# STM32L4R5AGI6 register map
File version: 1.0
Registers are 32-bit, access not given, reset 0x0 unless marked. A register's access mark holds for its fields unless they carry their own. Offsets are from the block's base; [hi:lo] are bit positions; {n}, {i} and the like mark numbered series; 'fields as' and 'values as' point back to an identical list.

## TIM6
Base 0x40001000
Same registers: TIM7 0x40001400
0x00 CR1
  [11] UIFREMA, [7] ARPE, [31:4] s, [3] OPM, [2] URS, [1] UDIS, [0] CEN
0x04 CR2
  [6:4] MMS, [31:0] s
0x0C DIER
  [8] UDE, [31:1] s, [0] UIE
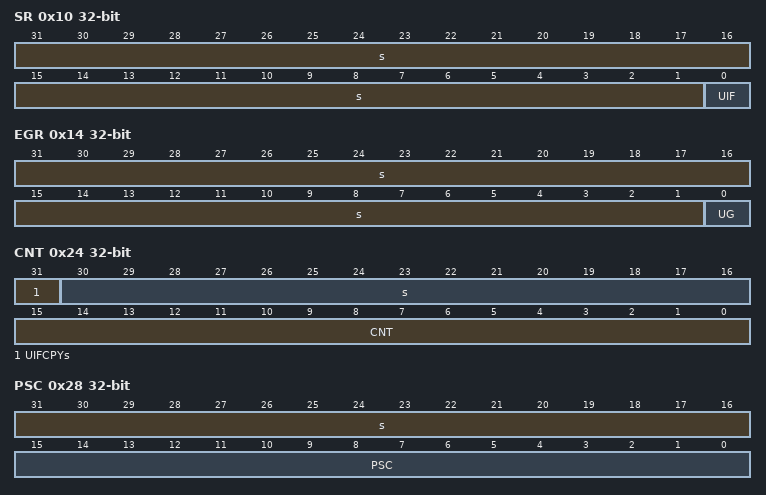
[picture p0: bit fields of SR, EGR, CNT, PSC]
0x10 SR
  [31:1] s, [0] UIF
0x14 EGR
  [31:1] s, [0] UG
0x24 CNT
  [31] UIFCPYs, [30:16] s, [15:0] CNT
0x28 PSC
  [31:16] s, [15:0] PSC
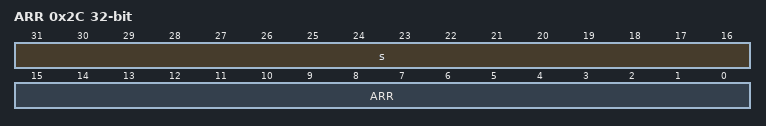
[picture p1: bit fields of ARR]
0x2C ARR
  [31:16] s, [15:0] ARR

## RTC
Base 0x40002800
0x00 TR
  [22] PM, [21:20] HT, [19:16] HU, [14:12] MNT, [11:8] MNU, [31:7] s, [6:4] ST, [3:0] SU
0x04 DR
  [23:20] YT, [19:16] YU, [15:13] WDU, [12] MT, [11:8] MU, [31:6] s, [5:4] DT, [3:0] DU
0x08 CR
  [24] ITSE, [23] COE, [22:21] OSEL, [20] POL, [19] COSEL, [18] BKP, [17] SUB1H, [16] ADD1H, [15] TSIE, [14] WUTIE, [13] ALRBIE, [12] ALRAIE, [11] TSE, [10] WUTE, [9] ALRBE, [8] ALRAE, [31:7] s, [6] FMT, [5] BYPSHAD, [4] REFCKON, [3] TSEDGE, [2:0] WUCKSEL
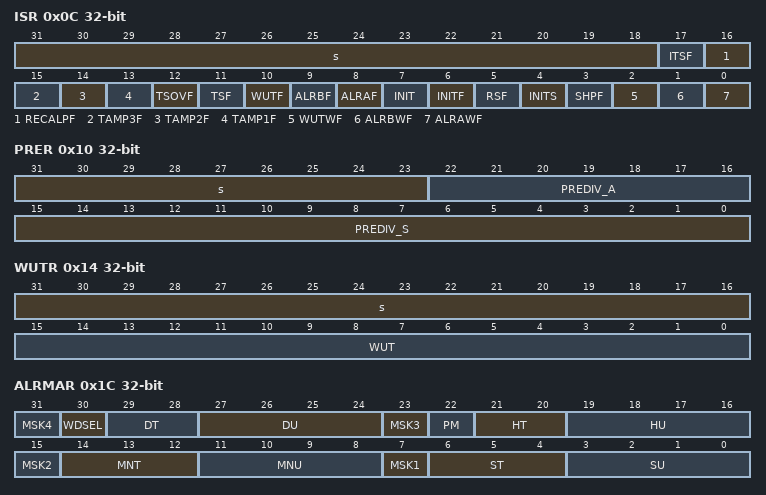
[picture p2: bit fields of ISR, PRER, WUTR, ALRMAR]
0x0C ISR
  [31:18] s, [17] ITSF, [16] RECALPF, [15] TAMP3F, [14] TAMP2F, [13] TAMP1F, [12] TSOVF, [11] TSF, [10] WUTF, [9] ALRBF, [8] ALRAF, [7] INIT, [6] INITF, [5] RSF, [4] INITS, [3] SHPF, [2] WUTWF, [1] ALRBWF, [0] ALRAWF
0x10 PRER
  [31:23] s, [22:16] PREDIV_A, [15:0] PREDIV_S
0x14 WUTR
  [31:16] s, [15:0] WUT
0x1C ALRMAR
  [8n-1] MSK{n} (n=1..4), [30] WDSEL, [29:28] DT, [27:24] DU, [22] PM, [21:20] HT, [19:16] HU, [14:12] MNT, [11:8] MNU, [6:4] ST, [3:0] SU
0x20 ALRMBR
  [31] MSK4, [30] WDSEL, [29:28] DT, [27:24] DU, [23] MSK3, [22] PM, [21:20] HT, [19:16] HU, [14:12] MNT, [11:8] MNU, [15:7] MSK2, [6:4] ST, [3:0] SU
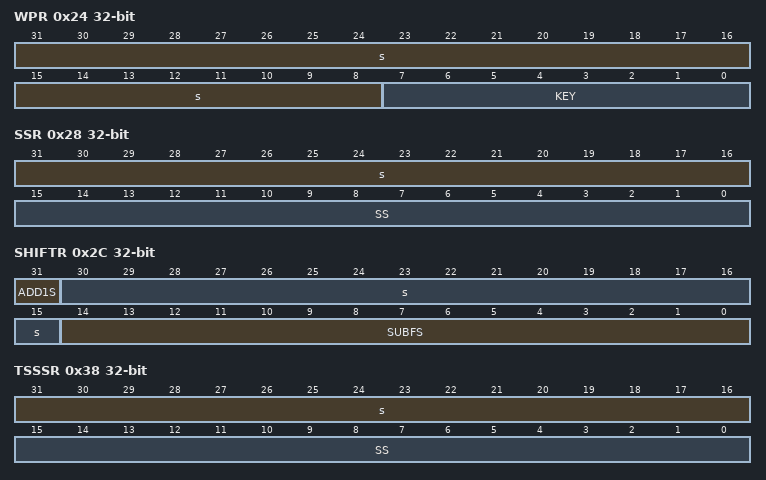
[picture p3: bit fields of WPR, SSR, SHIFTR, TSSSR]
0x24 WPR
  [31:8] s, [7:0] KEY
0x28 SSR
  [31:16] s, [15:0] SS
0x2C SHIFTR
  [31] ADD1S, [30:15] s, [14:0] SUBFS
0x30 TSTR
  fields as TR
0x34 TSDR
  [15:13] WDU, [12] MT, [11:8] MU, [31:6] s, [5:4] DT, [3:0] DU
0x38 TSSSR
  [31:16] s, [15:0] SS
0x3C CALR
  [15] CALP, [14] CALW8, [13] CALW16, [31:9] s, [8:0] CALM
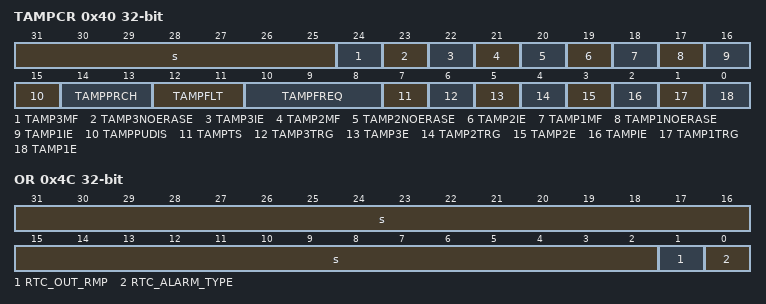
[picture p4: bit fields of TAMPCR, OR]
0x40 TAMPCR
  [31:25] s, [24] TAMP3MF, [23] TAMP3NOERASE, [22] TAMP3IE, [21] TAMP2MF, [20] TAMP2NOERASE, [19] TAMP2IE, [18] TAMP1MF, [17] TAMP1NOERASE, [16] TAMP1IE, [15] TAMPPUDIS, [14:13] TAMPPRCH, [12:11] TAMPFLT, [10:8] TAMPFREQ, [7] TAMPTS, [6] TAMP3TRG, [5] TAMP3E, [4] TAMP2TRG, [3] TAMP2E, [2] TAMPIE, [1] TAMP1TRG, [0] TAMP1E
0x44 ALRMASSR
  [27:24] MASKSS, [31:15] s, [14:0] SS
0x48 ALRMBSSR
  [27:24] MASKSS, [31:15] s, [14:0] SS
0x4C OR
  [31:2] s, [1] RTC_OUT_RMP, [0] RTC_ALARM_TYPE
{0x50+4i} BKP{i}R (i=0..31)
  [31:0] BKP

## WWDG
Base 0x40002C00
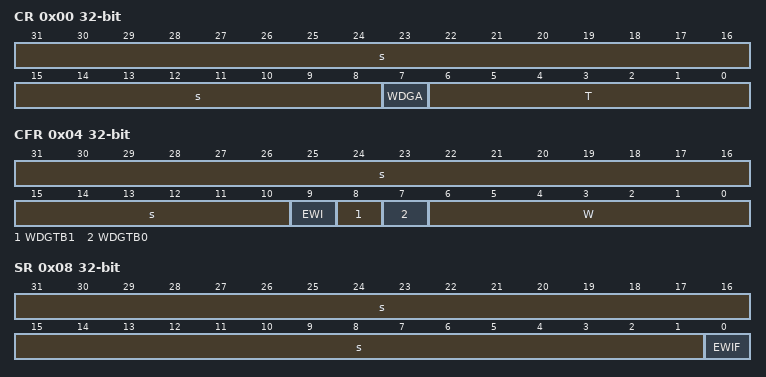
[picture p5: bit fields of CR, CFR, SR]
0x00 CR
  [31:8] s, [7] WDGA, [6:0] T
0x04 CFR
  [31:10] s, [9] EWI, [8] WDGTB1, [7] WDGTB0, [6:0] W
0x08 SR
  [31:1] s, [0] EWIF

## IWDG
Base 0x40003000
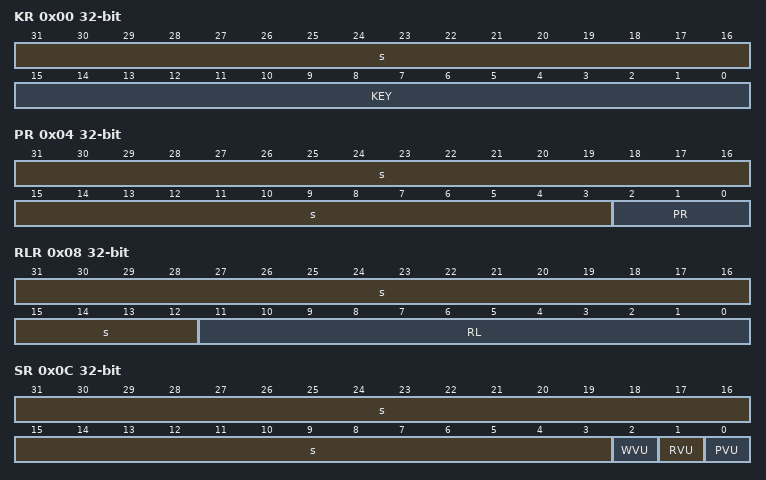
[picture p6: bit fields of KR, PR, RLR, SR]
0x00 KR
  [31:16] s, [15:0] KEY
0x04 PR
  [31:3] s, [2:0] PR
0x08 RLR
  [31:12] s, [11:0] RL
0x0C SR
  [31:3] s, [2] WVU, [1] RVU, [0] PVU
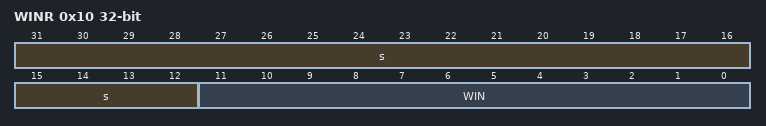
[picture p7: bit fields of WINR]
0x10 WINR
  [31:12] s, [11:0] WIN

## SPI2
Base 0x40003800
Same registers: SPI3 0x40003C00, SPI1 0x40013000
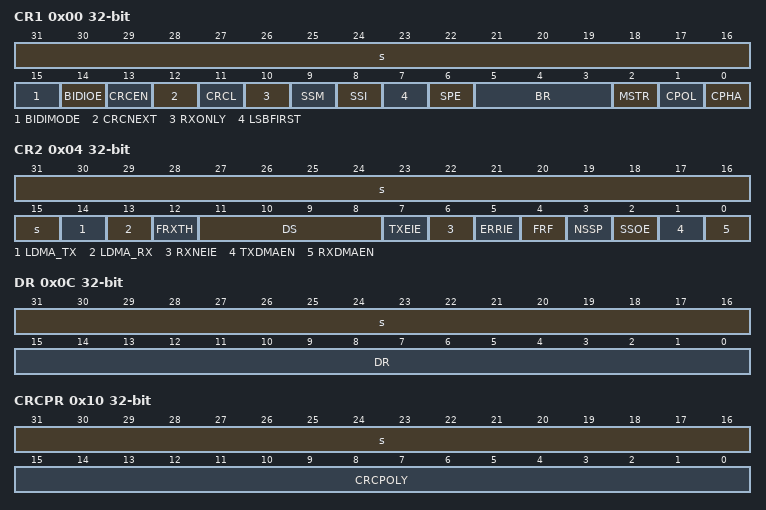
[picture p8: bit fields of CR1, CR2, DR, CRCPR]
0x00 CR1
  [31:16] s, [15] BIDIMODE, [14] BIDIOE, [13] CRCEN, [12] CRCNEXT, [11] CRCL, [10] RXONLY, [9] SSM, [8] SSI, [7] LSBFIRST, [6] SPE, [5:3] BR, [2] MSTR, [1] CPOL, [0] CPHA
0x04 CR2
  [31:15] s, [14] LDMA_TX, [13] LDMA_RX, [12] FRXTH, [11:8] DS, [7] TXEIE, [6] RXNEIE, [5] ERRIE, [4] FRF, [3] NSSP, [2] SSOE, [1] TXDMAEN, [0] RXDMAEN
0x08 SR
  [12:11] FTLVL, [10:9] FRLVL, [8] FRE, [7] BSY, [6] OVR, [5] MODF, [4] CRCERR, [31:2] s, [1] TXE, [0] RXNE
0x0C DR
  [31:16] s, [15:0] DR
0x10 CRCPR
  [31:16] s, [15:0] CRCPOLY
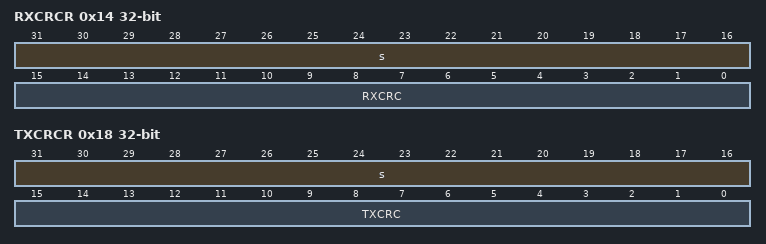
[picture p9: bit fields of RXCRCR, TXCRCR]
0x14 RXCRCR
  [31:16] s, [15:0] RXCRC
0x18 TXCRCR
  [31:16] s, [15:0] TXCRC

## USART2
Base 0x40004400
Same registers: USART3 0x40004800, UART4 0x40004C00, UART5 0x40005000, USART1 0x40013800
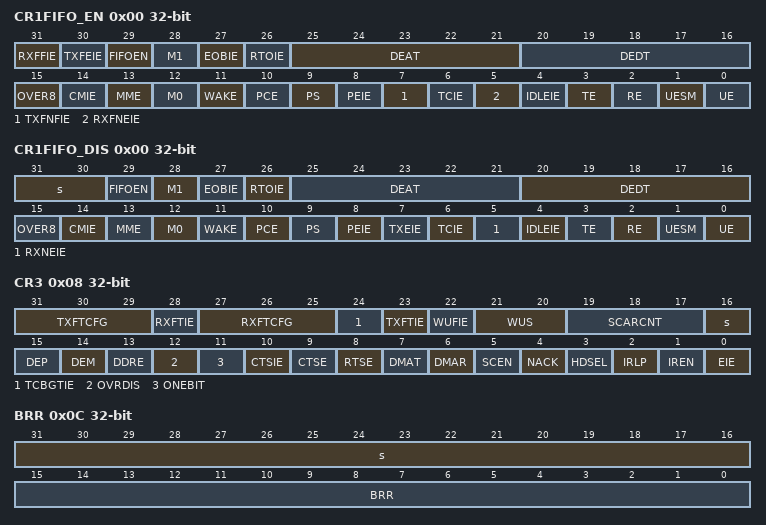
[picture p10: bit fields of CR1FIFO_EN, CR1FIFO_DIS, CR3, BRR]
0x00 CR1FIFO_EN
  [31] RXFFIE, [30] TXFEIE, [29] FIFOEN, [28] M1, [27] EOBIE, [26] RTOIE, [25:21] DEAT, [20:16] DEDT, [15] OVER8, [14] CMIE, [13] MME, [12] M0, [11] WAKE, [10] PCE, [9] PS, [8] PEIE, [7] TXFNFIE, [6] TCIE, [5] RXFNEIE, [4] IDLEIE, [3] TE, [2] RE, [1] UESM, [0] UE
0x00 CR1FIFO_DIS
  [31:30] s, [29] FIFOEN, [28] M1, [27] EOBIE, [26] RTOIE, [25:21] DEAT, [20:16] DEDT, [15] OVER8, [14] CMIE, [13] MME, [12] M0, [11] WAKE, [10] PCE, [9] PS, [8] PEIE, [7] TXEIE, [6] TCIE, [5] RXNEIE, [4] IDLEIE, [3] TE, [2] RE, [1] UESM, [0] UE
0x04 CR2
  [31:24] ADD, [23] RTOEN, [22:21] ABRMOD, [20] ABREN, [19] MSBFIRST, [18] DATAINV, [17] TXINV, [16] RXINV, [15] SWAP, [14] LINEN, [13:12] STOP, [11] CLKEN, [10] CPOL, [9] CPHA, [8] LBCL, [6] LBDIE, [5] LBDL, [4] ADDM7, [3] DIS_NSS, [7:1] s, [0] SLVEN
0x08 CR3
  [31:29] TXFTCFG, [28] RXFTIE, [27:25] RXFTCFG, [24] TCBGTIE, [23] TXFTIE, [22] WUFIE, [21:20] WUS, [19:17] SCARCNT, [16] s, [15] DEP, [14] DEM, [13] DDRE, [12] OVRDIS, [11] ONEBIT, [10] CTSIE, [9] CTSE, [8] RTSE, [7] DMAT, [6] DMAR, [5] SCEN, [4] NACK, [3] HDSEL, [2] IRLP, [1] IREN, [0] EIE
0x0C BRR
  [31:16] s, [15:0] BRR
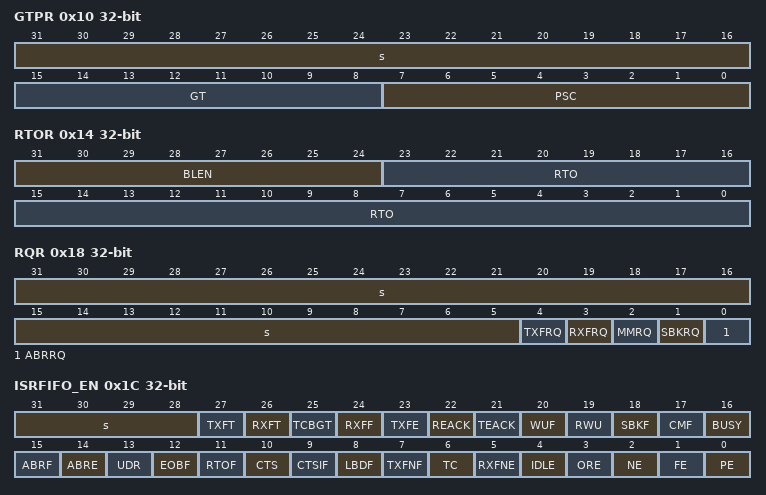
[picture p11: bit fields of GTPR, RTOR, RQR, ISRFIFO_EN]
0x10 GTPR
  [31:16] s, [15:8] GT, [7:0] PSC
0x14 RTOR
  [31:24] BLEN, [23:0] RTO
0x18 RQR
  [31:5] s, [4] TXFRQ, [3] RXFRQ, [2] MMRQ, [1] SBKRQ, [0] ABRRQ
0x1C ISRFIFO_EN
  [31:28] s, [27] TXFT, [26] RXFT, [25] TCBGT, [24] RXFF, [23] TXFE, [22] REACK, [21] TEACK, [20] WUF, [19] RWU, [18] SBKF, [17] CMF, [16] BUSY, [15] ABRF, [14] ABRE, [13] UDR, [12] EOBF, [11] RTOF, [10] CTS, [9] CTSIF, [8] LBDF, [7] TXFNF, [6] TC, [5] RXFNE, [4] IDLE, [3] ORE, [2] NE, [1] FE, [0] PE
0x1C ISRFIFO_DIS
  [25] TCBGT, [31:23] s, [22] REACK, [21] TEACK, [20] WUF, [19] RWU, [18] SBKF, [17] CMF, [16] BUSY, [15] ABRF, [14] ABRE, [13] UDR, [12] EOBF, [11] RTOF, [10] CTS, [9] CTSIF, [8] LBDF, [7] TXE, [6] TC, [5] RXNE, [4] IDLE, [3] ORE, [2] NE, [1] FE, [0] PE
0x20 ICR
  [20] WUCF, [17] CMCF, [13] UDRCF, [12] EOBCF, [11] RTOCF, [31:10] s, [9] CTSCF, [8] LBDCF, [7] TCBGTCF, [6] TCCF, [5] TXFECF, [4] IDLECF, [3] ORECF, [2] NECF, [1] FECF, [0] PECF
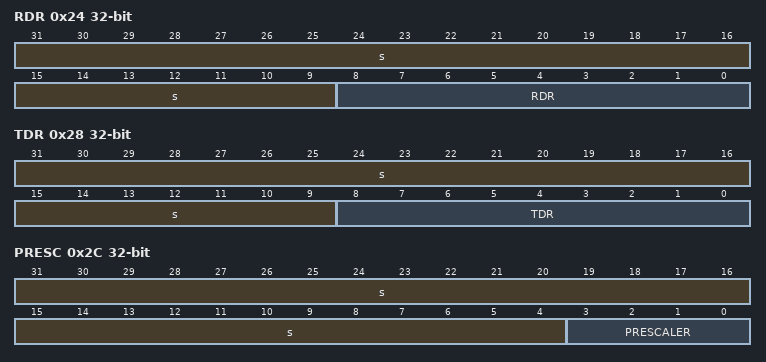
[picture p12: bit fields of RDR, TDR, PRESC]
0x24 RDR
  [31:9] s, [8:0] RDR
0x28 TDR
  [31:9] s, [8:0] TDR
0x2C PRESC
  [31:4] s, [3:0] PRESCALER
